# TLE986x register map
File version: 2.5
Registers are 32-bit, read-write, reset 0x0 unless marked. A register's access mark holds for its fields unless they carry their own. Offsets are from the block's base; [hi:lo] are bit positions; 'fields as' and 'values as' point back to an identical list.

## LIN
Base 0x4801E000
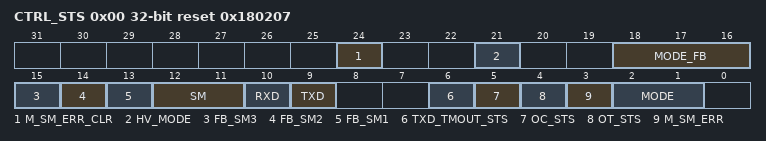
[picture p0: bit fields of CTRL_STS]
0x00 CTRL_STS access per field reset 0x180207 (reset mask 0xFFF81BFF) — LIN Transceiver Control and Status
  [24] M_SM_ERR_CLR wo — LIN Transceiver Mode or Slope Mode Error Clear
    0=Mode or Slope Mode Error (Status not clear); 1=Mode or Slope Mode Error (Status clear)
  [21] HV_MODE rw — LIN Transceiver High Voltage Input - Output Mode
    0=DISABLE (High Voltage Mode Entry is disabled); 1=ENABLE (High Voltage Mode Entry is enabled)
  [18:16] MODE_FB ro — Feedback Signals for LIN Transmitter Mode Settings
  [15] FB_SM3 ro — Feedback Signal 3 for Slope Mode Setting
  [14] FB_SM2 ro — Feedback Signal 2 for Slope Mode Setting
  [13] FB_SM1 ro — Feedback Signal 1 for Slope Mode Setting
  [12:11] SM rw — LIN Transmitter Slope mode control
    0=Normal Slope Mode (for max. 20 kBaud); 1=Fast Slope Mode (for max. 40 kBaud); 2=Low Slope Mode (for max. 10.4 kBaud); 3=Flash Mode (for max. 150 kBaud#)
  [10] RXD ro — Output Signal of Receiver
  [9] TXD rw — LIN Transmitter switch on (only used when LIN_HV_MODE is set)
    0=Pull Down LIN Line (Transmitter is switched on); 1=Pull Up Resistor is active (Transmitter is switched off)
  [6] TXD_TMOUT_STS ro — LIN TXD time-out status
    0=NO_TIMEOUT (no time-out occured); 1=TIMEOUT (time-out occured)
  [5] OC_STS ro — LIN Receiver Overcurrent Status
    0=no Overcurrent (overcurrent status occured); 1=overcurrent status occured
  [4] OT_STS ro — LIN Receiver Overtemperature Status
    0=no Overtemperature (overtemperature occured); 1=overtemperature occured
  [3] M_SM_ERR ro — LIN Transceiver Mode or Slope Mode Error
    0=no Mode or Slope Mode Error (Status (see corresponding Feedback registers)); 1=Mode or Slope Mode Error (Status (see corresponding Feedback registers))
  [2:1] MODE rw — LIN transceiver power mode control
    0=LIN Sleep Mode (LIN module switched to LIN Sleep Mode); 1=LIN Receive-Only Mode (LIN module switched to LIN Receive Only Mode); 2=n.u. (not used); 3=LIN Normal Mode (LIN module switched to LIN Normal Mode)

## MF
Base 0x48018000
0x00 P2_ADCSEL_CTRL — Port 2 ADC Selection Control Register
  [10] ADC1_CH1_SEL — ADC1 Channel 1 Input Selection
    1=CS_AMP (Current Sense Amplifier is conncted to Ch1 of ADC1)
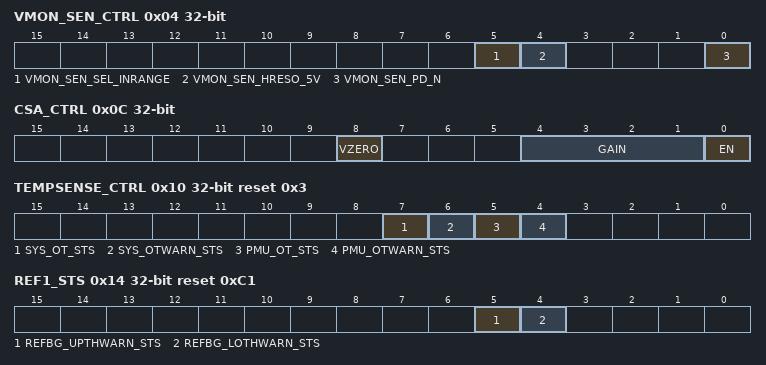
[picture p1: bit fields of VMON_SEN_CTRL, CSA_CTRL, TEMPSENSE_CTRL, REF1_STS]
0x04 VMON_SEN_CTRL — Supply Sense Control Register
  [5] VMON_SEN_SEL_INRANGE — Monitoring Input Attenuator Select Inputrange
    0=0 - 18V Range (is selected); 1=0 - 28V Range (is selected)
  [4] VMON_SEN_HRESO_5V — Monitoring Input Attenuator High Impedance Output Control
    0=High Resistive Output Disable (Connection to ADC input low ohmic); 1=High Resistive Output Enable (Connection to ADC input high ohmic)
  [0] VMON_SEN_PD_N — Monitoring Input Attenuator enable
    0=DISABLE (Attenuator switched off); 1=ENABLE (Attenuator switched on)
0x0C CSA_CTRL — Current Sense Amplifier Control Register
  [8] VZERO — Current Sense Output Voltage Level to Ground
    0=VOUT (Output Voltage is VOUT of Amplifier); 1=GROUND (Output Voltage is Ground of Feedback Network)
  [4:1] GAIN — OPA gain setting
    0=GMIN; 15=GMAX
  [0] EN — OPA enable
    0=DISABLE (OPA switched off); 1=ENABLE (OPA switched on)
0x10 TEMPSENSE_CTRL ro reset 0x3 — Temperature Sensor Control Register
  [all] fields
    0=INACTIVE (write clears status); 1=ACTIVE (interrupt status set)
  [7] SYS_OT_STS — System Overtemperature (MU) Status
  [6] SYS_OTWARN_STS — System Overtemperature Warning (MU) Status
  [5] PMU_OT_STS — PMU Regulator Overtemperature (MU) Status
  [4] PMU_OTWARN_STS — PMU Regulator Overtemperature Warning (MU) Status
0x14 REF1_STS ro reset 0xC1 — Reference 1 Status Register
  [5] REFBG_UPTHWARN_STS — Status for Overvoltage Threshold Measurement of internal VAREF
    0=UPPER_TRIG_RESET (write clears status); 1=UPPER_TRIG_SET (trigger status set)
  [4] REFBG_LOTHWARN_STS — Status for Undervoltage Threshold Measurement of internal VAREF
    values as REFBG_UPTHWARN_STS
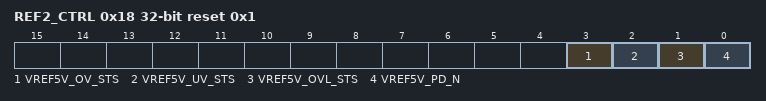
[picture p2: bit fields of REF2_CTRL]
0x18 REF2_CTRL access per field reset 0x1 — Reference 2 Control Register
  [3] VREF5V_OV_STS ro — ADC1 Bit Reference Voltage Generation Overvoltage Bit
    0=no Overvoltage detected; 1=Overvoltage detected
  [2] VREF5V_UV_STS ro — ADC1 Bit Reference Voltage Generation Undervoltage Bit
    0=no Undervoltage detected; 1=Undervoltage detected
  [1] VREF5V_OVL_STS ro — ADC1 Bit Reference Voltage Generation Over Load Bit
    0=no OVERLOAD detected; 1=OVERLOAD (OVERLOAD detected)
  [0] VREF5V_PD_N rw — ADC1 Bit Reference Voltage Generation Power Down Bit
    0=DISABLED (Power Down); 1=ACTIVE (no Power Down)
